# AT32F421xx register map
Vendor: Keil; Series: AT32F421; File version: 1.0
CPU: CM4 r0p1, little endian, no MPU, FPU, 4 interrupt priority bits
Registers are 32-bit, read-write, reset 0x0 unless marked. A register's access mark holds for its fields unless they carry their own. Offsets are from the block's base; [hi:lo] are bit positions.

## EFC
Base 0x40022000
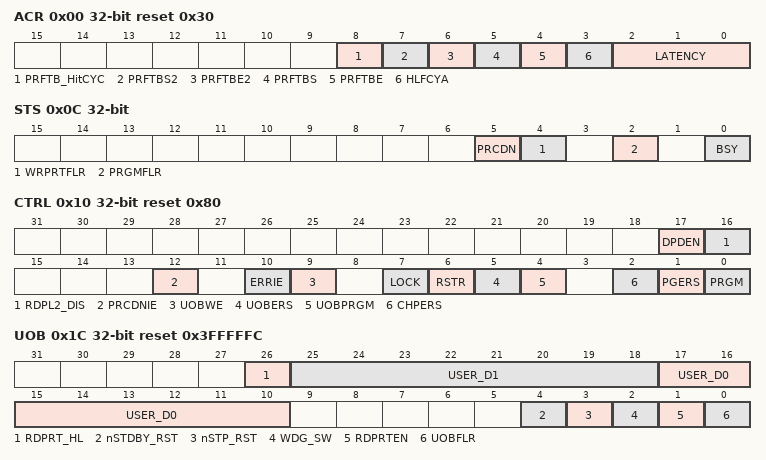
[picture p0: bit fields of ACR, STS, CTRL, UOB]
0x00 ACR reset 0x30 — Flash access control register
  [8] PRFTB_HitCYC — Prefetch buffer hit cycle
  [7] PRFTBS2 ro — Prefetch buffer2 status
  [6] PRFTBE2 — Prefetch buffer2 enable
  [5] PRFTBS ro — Prefetch buffer status
  [4] PRFTBE — Prefetch buffer enable
  [3] HLFCYA — Flash half cycle access enable
  [2:0] LATENCY
0x04 FCKEY wo — Flash key register
  [31:0] KEY — FPEC key
0x08 OPT2KEYR wo — Flash option key register
  [31:0] OTP2KEY — Option byte key
0x0C STS — Status register
  [5] PRCDN — End of operation
  [4] WRPRTFLR — Write protection error
  [2] PRGMFLR — Programming error
  [0] BSY ro — Busy
0x10 CTRL reset 0x80 — Control register
  [17] DPDEN ro — Low-power mode enable
  [16] RDPL2_DIS wo — Trigger HW to erase OTP2 when RDP level 2
  [12] PRCDNIE — End of operation interrupt enable
  [10] ERRIE — Error interrupt enable
  [9] UOBWE — Option bytes write enable
  [7] LOCK
  [6] RSTR — Start
  [5] UOBERS — Option byte erase
  [4] UOBPRGM — Option byte programming
  [2] CHPERS — Mass Erase
  [1] PGERS — Page Erase
  [0] PRGM — Programming
0x14 ADDR wo — Flash address register
  [31:0] TA — Flash Address
0x1C UOB ro reset 0x3FFFFFC — Option byte register
  [26] RDPRT_HL — RDP High level
  [25:18] USER_D1
  [17:10] USER_D0
  [4] nSTDBY_RST
  [3] nSTP_RST
  [2] WDG_SW
  [1] RDPRTEN — Read protection
  [0] UOBFLR — Option byte error
0x20 WRPRT ro reset 0xFFFFFFFF — Write protection register
  [31:0] WRPRTBMP — Write protect
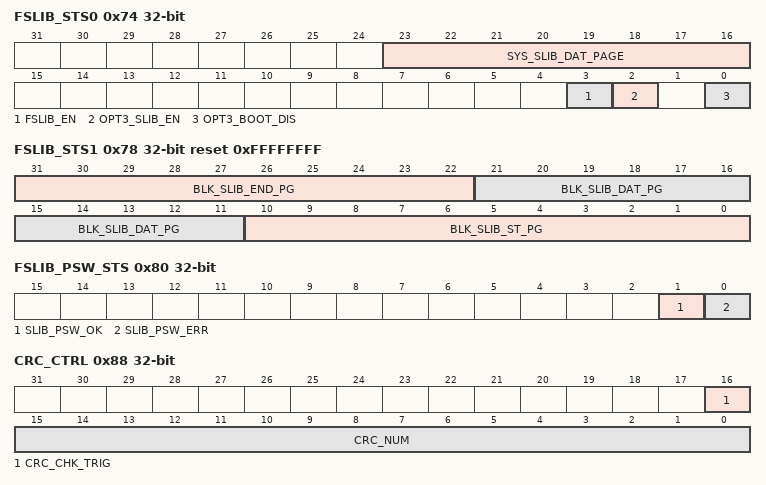
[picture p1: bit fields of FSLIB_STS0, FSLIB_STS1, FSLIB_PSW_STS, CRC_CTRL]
0x74 FSLIB_STS0 ro — Flash SLIB configuration data0 Register
  [23:16] SYS_SLIB_DAT_PAGE — Slib data page in system memory
  [3] FSLIB_EN — Slib code enable in flash
  [2] OPT3_SLIB_EN — Slib code enable in system memory
  [0] OPT3_BOOT_DIS — Boot mode disable in system memory
0x78 FSLIB_STS1 ro reset 0xFFFFFFFF — Flash SLIB configuration data1 Register
  [31:22] BLK_SLIB_END_PG — The SLIB code end address in main block
  [21:11] BLK_SLIB_DAT_PG — The SLIB data code start address in main block
  [10:0] BLK_SLIB_ST_PG — The SLIB code start address in main block
0x7C FSLIB_PSW_CLR wo reset 0xFFFFFFFF — Flash SLIB PASSWORD Register
  [31:0] FSLIB_PSW_CLR — SLIB password register, used to disable SLIB code
0x80 FSLIB_PSW_STS ro — Flash SLIB PASSWORD status Register
  [1] SLIB_PSW_OK — Password match, and password is not equal to 0xFFFFFFFF
  [0] SLIB_PSW_ERR — Password mismatch, and password is not equal to 0xFFFFFFFF
0x84 CRC_AR write — Flash CRC data start Register
  [31:0] FCRC_ADDR — The CRC32 verification start address of user code or SLIB code
0x88 CRC_CTRL — Flash CRC Controll Register
  [16] CRC_CHK_TRIG wo — Trigger to calculate CRC
  [15:0] CRC_NUM — Data number for CRC calculation. Unit: sector
0x8C CRC_OUTR ro — Flash CRC verification output Register
  [31:0] FCRC_OUT — CRC32 verification result of flash user code or SLIB code
0x160 FSLIB_SET_PSW wo — Flash SET SLIB PASSWORD Register
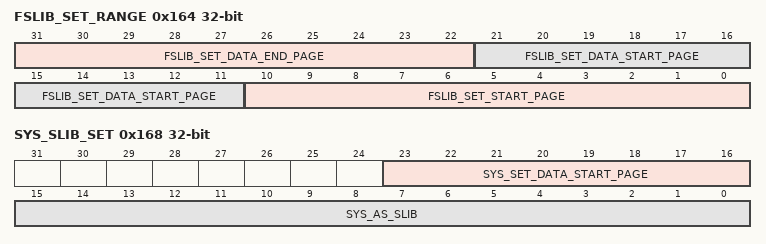
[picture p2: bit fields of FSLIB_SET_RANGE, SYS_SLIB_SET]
0x164 FSLIB_SET_RANGE wo — Flash SET SLIB RANGE Register
  [31:22] FSLIB_SET_DATA_END_PAGE — The SLIB code end address in main block
  [21:11] FSLIB_SET_DATA_START_PAGE — The SLIB data code start address in main block
  [10:0] FSLIB_SET_START_PAGE — The SLIB code start address in main block
0x168 SYS_SLIB_SET wo — SYSTEM MEMORY SET SLIB Register
  [23:16] SYS_SET_DATA_START_PAGE — Slib data start page in system memory
  [15:0] SYS_AS_SLIB — Configure SYSTEM MEMORY AS SLIB AREA
0x16C SYS_BOOT_DIS_SET wo — SYSTEM MEMORY BOOT DIS SET Register
  [7:0] BOOT_DIS_SET — DISABLE SYSTEM MEMORY BOOT MODE
0x170 FSLIB_KEYR wo — Flash SLIB KEY Register
  [31:0] FSLIB_KEYR — Write 0xA35F_6D24 to unlock SLIB_SET_PSW SLIB_SET_RANGE SYS_SLIB_SET SYS_BOOT_DIS_SET registers
